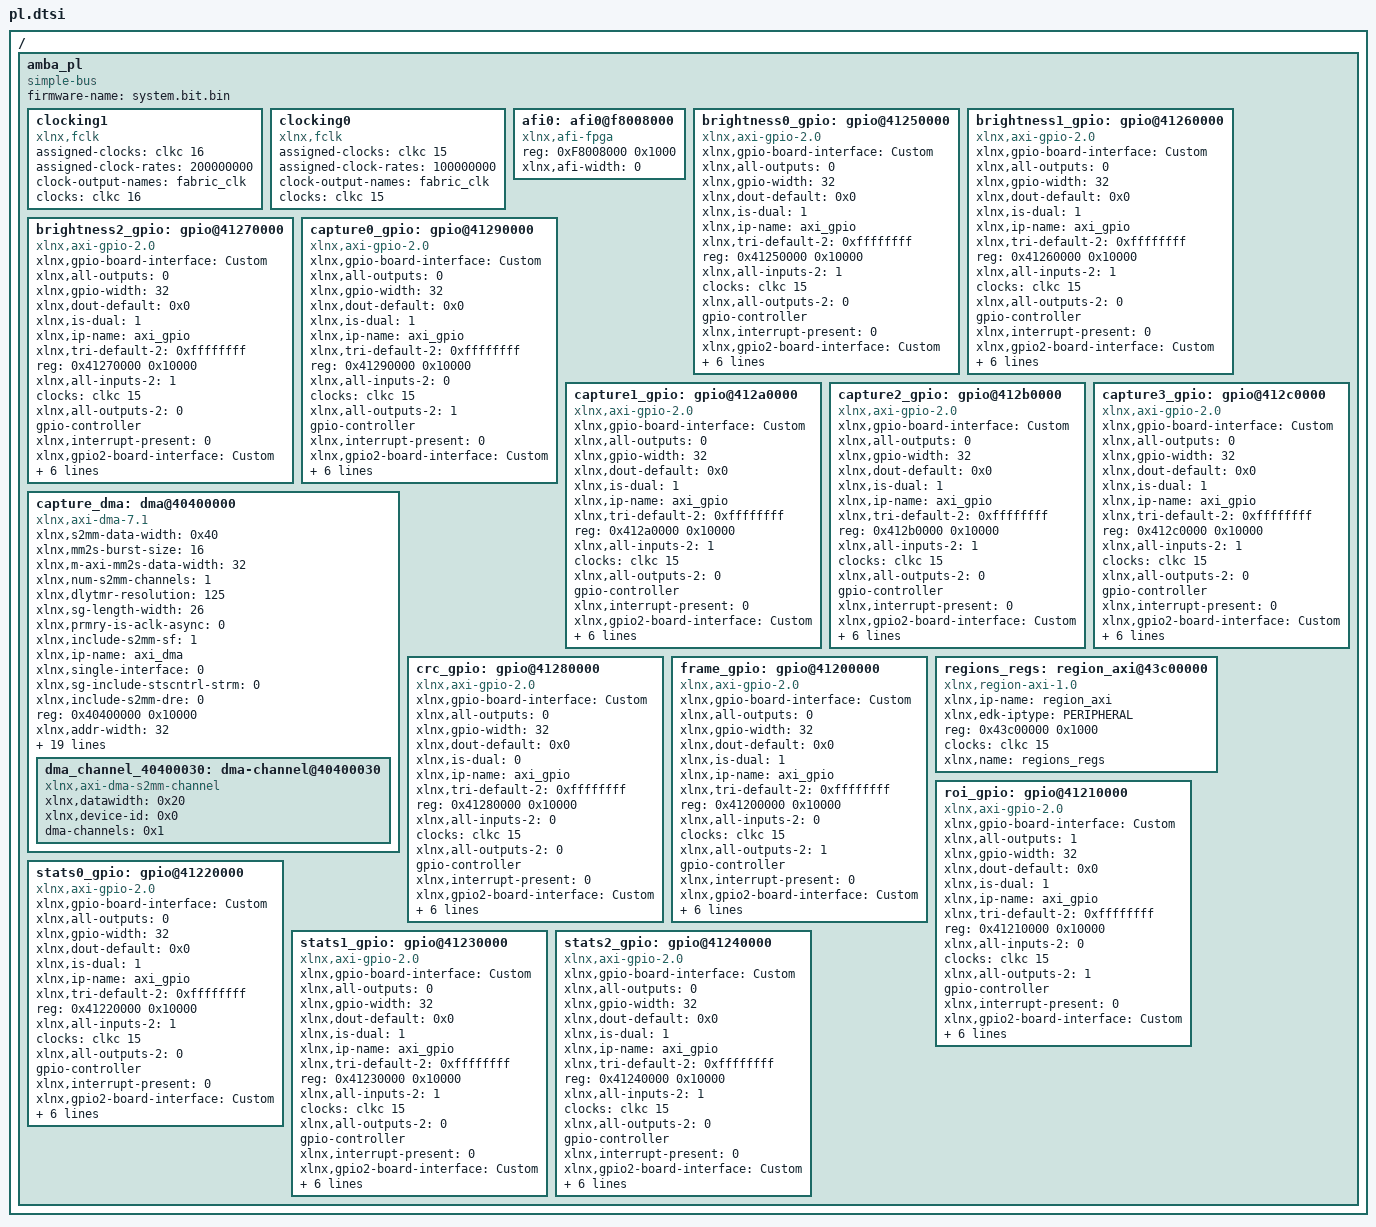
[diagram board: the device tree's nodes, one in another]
/ {
	amba_pl: amba_pl {
		ranges;
		compatible = "simple-bus";
		#address-cells = <1>;
		#size-cells = <1>;
		firmware-name = "system.bit.bin";
		clocking1: clocking1 {
			compatible = "xlnx,fclk";
			assigned-clocks = <&clkc 16>;
			assigned-clock-rates = <200000000>;
			#clock-cells = <0>;
			clock-output-names = "fabric_clk";
			clocks = <&clkc 16>;
		};
		clocking0: clocking0 {
			compatible = "xlnx,fclk";
			assigned-clocks = <&clkc 15>;
			assigned-clock-rates = <100000000>;
			#clock-cells = <0>;
			clock-output-names = "fabric_clk";
			clocks = <&clkc 15>;
		};
		afi0: afi0@f8008000 {
			status = "okay";
			compatible = "xlnx,afi-fpga";
			#address-cells = <1>;
			reg = <0xF8008000 0x1000>;
			#size-cells = <0>;
			xlnx,afi-width = <0>;
		};
		brightness0_gpio: gpio@41250000 {
			xlnx,gpio-board-interface = "Custom";
			compatible = "xlnx,axi-gpio-2.0" , "xlnx,xps-gpio-1.00.a";
			xlnx,all-outputs = <0>;
			#gpio-cells = <2>;
			xlnx,gpio-width = <32>;
			xlnx,dout-default = <0x0>;
			xlnx,is-dual = <1>;
			xlnx,ip-name = "axi_gpio";
			xlnx,tri-default-2 = <0xffffffff>;
			reg = <0x41250000 0x10000>;
			xlnx,all-inputs-2 = <1>;
			clocks = <&clkc 15>;
			xlnx,all-outputs-2 = <0>;
			gpio-controller;
			xlnx,interrupt-present = <0>;
			xlnx,gpio2-board-interface = "Custom";
			xlnx,edk-iptype = "PERIPHERAL";
			xlnx,dout-default-2 = <0x0>;
			status = "okay";
			xlnx,gpio2-width = <32>;
			clock-names = "s_axi_aclk";
			xlnx,tri-default = <0xffffffff>;
			xlnx,name = "brightness0_gpio";
			xlnx,all-inputs = <1>;
		};
		brightness1_gpio: gpio@41260000 {
			xlnx,gpio-board-interface = "Custom";
			compatible = "xlnx,axi-gpio-2.0" , "xlnx,xps-gpio-1.00.a";
			xlnx,all-outputs = <0>;
			#gpio-cells = <2>;
			xlnx,gpio-width = <32>;
			xlnx,dout-default = <0x0>;
			xlnx,is-dual = <1>;
			xlnx,ip-name = "axi_gpio";
			xlnx,tri-default-2 = <0xffffffff>;
			reg = <0x41260000 0x10000>;
			xlnx,all-inputs-2 = <1>;
			clocks = <&clkc 15>;
			xlnx,all-outputs-2 = <0>;
			gpio-controller;
			xlnx,interrupt-present = <0>;
			xlnx,gpio2-board-interface = "Custom";
			xlnx,edk-iptype = "PERIPHERAL";
			xlnx,dout-default-2 = <0x0>;
			status = "okay";
			xlnx,gpio2-width = <32>;
			clock-names = "s_axi_aclk";
			xlnx,tri-default = <0xffffffff>;
			xlnx,name = "brightness1_gpio";
			xlnx,all-inputs = <1>;
		};
		brightness2_gpio: gpio@41270000 {
			xlnx,gpio-board-interface = "Custom";
			compatible = "xlnx,axi-gpio-2.0" , "xlnx,xps-gpio-1.00.a";
			xlnx,all-outputs = <0>;
			#gpio-cells = <2>;
			xlnx,gpio-width = <32>;
			xlnx,dout-default = <0x0>;
			xlnx,is-dual = <1>;
			xlnx,ip-name = "axi_gpio";
			xlnx,tri-default-2 = <0xffffffff>;
			reg = <0x41270000 0x10000>;
			xlnx,all-inputs-2 = <1>;
			clocks = <&clkc 15>;
			xlnx,all-outputs-2 = <0>;
			gpio-controller;
			xlnx,interrupt-present = <0>;
			xlnx,gpio2-board-interface = "Custom";
			xlnx,edk-iptype = "PERIPHERAL";
			xlnx,dout-default-2 = <0x0>;
			status = "okay";
			xlnx,gpio2-width = <32>;
			clock-names = "s_axi_aclk";
			xlnx,tri-default = <0xffffffff>;
			xlnx,name = "brightness2_gpio";
			xlnx,all-inputs = <1>;
		};
		capture0_gpio: gpio@41290000 {
			xlnx,gpio-board-interface = "Custom";
			compatible = "xlnx,axi-gpio-2.0" , "xlnx,xps-gpio-1.00.a";
			xlnx,all-outputs = <0>;
			#gpio-cells = <2>;
			xlnx,gpio-width = <32>;
			xlnx,dout-default = <0x0>;
			xlnx,is-dual = <1>;
			xlnx,ip-name = "axi_gpio";
			xlnx,tri-default-2 = <0xffffffff>;
			reg = <0x41290000 0x10000>;
			xlnx,all-inputs-2 = <0>;
			clocks = <&clkc 15>;
			xlnx,all-outputs-2 = <1>;
			gpio-controller;
			xlnx,interrupt-present = <0>;
			xlnx,gpio2-board-interface = "Custom";
			xlnx,edk-iptype = "PERIPHERAL";
			xlnx,dout-default-2 = <0x0>;
			status = "okay";
			xlnx,gpio2-width = <32>;
			clock-names = "s_axi_aclk";
			xlnx,tri-default = <0xffffffff>;
			xlnx,name = "capture0_gpio";
			xlnx,all-inputs = <1>;
		};
		capture1_gpio: gpio@412a0000 {
			xlnx,gpio-board-interface = "Custom";
			compatible = "xlnx,axi-gpio-2.0" , "xlnx,xps-gpio-1.00.a";
			xlnx,all-outputs = <0>;
			#gpio-cells = <2>;
			xlnx,gpio-width = <32>;
			xlnx,dout-default = <0x0>;
			xlnx,is-dual = <1>;
			xlnx,ip-name = "axi_gpio";
			xlnx,tri-default-2 = <0xffffffff>;
			reg = <0x412a0000 0x10000>;
			xlnx,all-inputs-2 = <1>;
			clocks = <&clkc 15>;
			xlnx,all-outputs-2 = <0>;
			gpio-controller;
			xlnx,interrupt-present = <0>;
			xlnx,gpio2-board-interface = "Custom";
			xlnx,edk-iptype = "PERIPHERAL";
			xlnx,dout-default-2 = <0x0>;
			status = "okay";
			xlnx,gpio2-width = <32>;
			clock-names = "s_axi_aclk";
			xlnx,tri-default = <0xffffffff>;
			xlnx,name = "capture1_gpio";
			xlnx,all-inputs = <1>;
		};
		capture2_gpio: gpio@412b0000 {
			xlnx,gpio-board-interface = "Custom";
			compatible = "xlnx,axi-gpio-2.0" , "xlnx,xps-gpio-1.00.a";
			xlnx,all-outputs = <0>;
			#gpio-cells = <2>;
			xlnx,gpio-width = <32>;
			xlnx,dout-default = <0x0>;
			xlnx,is-dual = <1>;
			xlnx,ip-name = "axi_gpio";
			xlnx,tri-default-2 = <0xffffffff>;
			reg = <0x412b0000 0x10000>;
			xlnx,all-inputs-2 = <1>;
			clocks = <&clkc 15>;
			xlnx,all-outputs-2 = <0>;
			gpio-controller;
			xlnx,interrupt-present = <0>;
			xlnx,gpio2-board-interface = "Custom";
			xlnx,edk-iptype = "PERIPHERAL";
			xlnx,dout-default-2 = <0x0>;
			status = "okay";
			xlnx,gpio2-width = <32>;
			clock-names = "s_axi_aclk";
			xlnx,tri-default = <0xffffffff>;
			xlnx,name = "capture2_gpio";
			xlnx,all-inputs = <1>;
		};
		capture3_gpio: gpio@412c0000 {
			xlnx,gpio-board-interface = "Custom";
			compatible = "xlnx,axi-gpio-2.0" , "xlnx,xps-gpio-1.00.a";
			xlnx,all-outputs = <0>;
			#gpio-cells = <2>;
			xlnx,gpio-width = <32>;
			xlnx,dout-default = <0x0>;
			xlnx,is-dual = <1>;
			xlnx,ip-name = "axi_gpio";
			xlnx,tri-default-2 = <0xffffffff>;
			reg = <0x412c0000 0x10000>;
			xlnx,all-inputs-2 = <1>;
			clocks = <&clkc 15>;
			xlnx,all-outputs-2 = <0>;
			gpio-controller;
			xlnx,interrupt-present = <0>;
			xlnx,gpio2-board-interface = "Custom";
			xlnx,edk-iptype = "PERIPHERAL";
			xlnx,dout-default-2 = <0x0>;
			status = "okay";
			xlnx,gpio2-width = <32>;
			clock-names = "s_axi_aclk";
			xlnx,tri-default = <0xffffffff>;
			xlnx,name = "capture3_gpio";
			xlnx,all-inputs = <1>;
		};
		capture_dma: dma@40400000 {
			compatible = "xlnx,axi-dma-7.1" , "xlnx,axi-dma-1.00.a";
			xlnx,s2mm-data-width = <0x40>;
			xlnx,mm2s-burst-size = <16>;
			xlnx,m-axi-mm2s-data-width = <32>;
			xlnx,num-s2mm-channels = <1>;
			xlnx,dlytmr-resolution = <125>;
			xlnx,sg-length-width = <26>;
			xlnx,prmry-is-aclk-async = <0>;
			xlnx,include-s2mm-sf = <1>;
			#dma-cells = <1>;
			xlnx,ip-name = "axi_dma";
			xlnx,single-interface = <0>;
			xlnx,sg-include-stscntrl-strm = <0>;
			xlnx,include-s2mm-dre = <0>;
			reg = <0x40400000 0x10000>;
			xlnx,addr-width = <32>;
			xlnx,include-s2mm = <1>;
			clocks = <&clkc 15>, <&clkc 15>, <&clkc 15>;
			xlnx,s-axis-s2mm-tdata-width = <32>;
			xlnx,micro-dma = <0>;
			xlnx,increase-throughput = <0>;
			xlnx,mm2s-data-width = <0x20>;
			xlnx,addrwidth = <0x20>;
			xlnx,include-sg;
			xlnx,sg-use-stsapp-length = <0>;
			xlnx,m-axis-mm2s-tdata-width = <32>;
			xlnx,edk-iptype = "PERIPHERAL";
			xlnx,s2mm-burst-size = <64>;
			xlnx,m-axi-s2mm-data-width = <64>;
			xlnx,num-mm2s-channels = <1>;
			xlnx,enable-multi-channel = <0>;
			status = "okay";
			xlnx,include-mm2s-sf = <1>;
			clock-names = "m_axi_s2mm_aclk" , "m_axi_sg_aclk" , "s_axi_lite_aclk";
			xlnx,include-mm2s = <0>;
			xlnx,include-mm2s-dre = <0>;
			xlnx,name = "capture_dma";
			dma_channel_40400030: dma-channel@40400030 {
				xlnx,datawidth = <0x20>;
				xlnx,device-id = <0x0>;
				compatible = "xlnx,axi-dma-s2mm-channel";
				dma-channels = <0x1>;
			};
		};
		crc_gpio: gpio@41280000 {
			xlnx,gpio-board-interface = "Custom";
			compatible = "xlnx,axi-gpio-2.0" , "xlnx,xps-gpio-1.00.a";
			xlnx,all-outputs = <0>;
			#gpio-cells = <2>;
			xlnx,gpio-width = <32>;
			xlnx,dout-default = <0x0>;
			xlnx,is-dual = <0>;
			xlnx,ip-name = "axi_gpio";
			xlnx,tri-default-2 = <0xffffffff>;
			reg = <0x41280000 0x10000>;
			xlnx,all-inputs-2 = <0>;
			clocks = <&clkc 15>;
			xlnx,all-outputs-2 = <0>;
			gpio-controller;
			xlnx,interrupt-present = <0>;
			xlnx,gpio2-board-interface = "Custom";
			xlnx,edk-iptype = "PERIPHERAL";
			xlnx,dout-default-2 = <0x0>;
			status = "okay";
			xlnx,gpio2-width = <32>;
			clock-names = "s_axi_aclk";
			xlnx,tri-default = <0xffffffff>;
			xlnx,name = "crc_gpio";
			xlnx,all-inputs = <1>;
		};
		frame_gpio: gpio@41200000 {
			xlnx,gpio-board-interface = "Custom";
			compatible = "xlnx,axi-gpio-2.0" , "xlnx,xps-gpio-1.00.a";
			xlnx,all-outputs = <0>;
			#gpio-cells = <2>;
			xlnx,gpio-width = <32>;
			xlnx,dout-default = <0x0>;
			xlnx,is-dual = <1>;
			xlnx,ip-name = "axi_gpio";
			xlnx,tri-default-2 = <0xffffffff>;
			reg = <0x41200000 0x10000>;
			xlnx,all-inputs-2 = <0>;
			clocks = <&clkc 15>;
			xlnx,all-outputs-2 = <1>;
			gpio-controller;
			xlnx,interrupt-present = <0>;
			xlnx,gpio2-board-interface = "Custom";
			xlnx,edk-iptype = "PERIPHERAL";
			xlnx,dout-default-2 = <0x0>;
			status = "okay";
			xlnx,gpio2-width = <32>;
			clock-names = "s_axi_aclk";
			xlnx,tri-default = <0xffffffff>;
			xlnx,name = "frame_gpio";
			xlnx,all-inputs = <1>;
		};
		regions_regs: region_axi@43c00000 {
			compatible = "xlnx,region-axi-1.0";
			status = "okay";
			clock-names = "s_axi_aclk";
			xlnx,ip-name = "region_axi";
			xlnx,edk-iptype = "PERIPHERAL";
			reg = <0x43c00000 0x1000>;
			clocks = <&clkc 15>;
			xlnx,name = "regions_regs";
		};
		roi_gpio: gpio@41210000 {
			xlnx,gpio-board-interface = "Custom";
			compatible = "xlnx,axi-gpio-2.0" , "xlnx,xps-gpio-1.00.a";
			xlnx,all-outputs = <1>;
			#gpio-cells = <2>;
			xlnx,gpio-width = <32>;
			xlnx,dout-default = <0x0>;
			xlnx,is-dual = <1>;
			xlnx,ip-name = "axi_gpio";
			xlnx,tri-default-2 = <0xffffffff>;
			reg = <0x41210000 0x10000>;
			xlnx,all-inputs-2 = <0>;
			clocks = <&clkc 15>;
			xlnx,all-outputs-2 = <1>;
			gpio-controller;
			xlnx,interrupt-present = <0>;
			xlnx,gpio2-board-interface = "Custom";
			xlnx,edk-iptype = "PERIPHERAL";
			xlnx,dout-default-2 = <0x0>;
			status = "okay";
			xlnx,gpio2-width = <32>;
			clock-names = "s_axi_aclk";
			xlnx,tri-default = <0xffffffff>;
			xlnx,name = "roi_gpio";
			xlnx,all-inputs = <0>;
		};
		stats0_gpio: gpio@41220000 {
			xlnx,gpio-board-interface = "Custom";
			compatible = "xlnx,axi-gpio-2.0" , "xlnx,xps-gpio-1.00.a";
			xlnx,all-outputs = <0>;
			#gpio-cells = <2>;
			xlnx,gpio-width = <32>;
			xlnx,dout-default = <0x0>;
			xlnx,is-dual = <1>;
			xlnx,ip-name = "axi_gpio";
			xlnx,tri-default-2 = <0xffffffff>;
			reg = <0x41220000 0x10000>;
			xlnx,all-inputs-2 = <1>;
			clocks = <&clkc 15>;
			xlnx,all-outputs-2 = <0>;
			gpio-controller;
			xlnx,interrupt-present = <0>;
			xlnx,gpio2-board-interface = "Custom";
			xlnx,edk-iptype = "PERIPHERAL";
			xlnx,dout-default-2 = <0x0>;
			status = "okay";
			xlnx,gpio2-width = <32>;
			clock-names = "s_axi_aclk";
			xlnx,tri-default = <0xffffffff>;
			xlnx,name = "stats0_gpio";
			xlnx,all-inputs = <1>;
		};
		stats1_gpio: gpio@41230000 {
			xlnx,gpio-board-interface = "Custom";
			compatible = "xlnx,axi-gpio-2.0" , "xlnx,xps-gpio-1.00.a";
			xlnx,all-outputs = <0>;
			#gpio-cells = <2>;
			xlnx,gpio-width = <32>;
			xlnx,dout-default = <0x0>;
			xlnx,is-dual = <1>;
			xlnx,ip-name = "axi_gpio";
			xlnx,tri-default-2 = <0xffffffff>;
			reg = <0x41230000 0x10000>;
			xlnx,all-inputs-2 = <1>;
			clocks = <&clkc 15>;
			xlnx,all-outputs-2 = <0>;
			gpio-controller;
			xlnx,interrupt-present = <0>;
			xlnx,gpio2-board-interface = "Custom";
			xlnx,edk-iptype = "PERIPHERAL";
			xlnx,dout-default-2 = <0x0>;
			status = "okay";
			xlnx,gpio2-width = <32>;
			clock-names = "s_axi_aclk";
			xlnx,tri-default = <0xffffffff>;
			xlnx,name = "stats1_gpio";
			xlnx,all-inputs = <1>;
		};
		stats2_gpio: gpio@41240000 {
			xlnx,gpio-board-interface = "Custom";
			compatible = "xlnx,axi-gpio-2.0" , "xlnx,xps-gpio-1.00.a";
			xlnx,all-outputs = <0>;
			#gpio-cells = <2>;
			xlnx,gpio-width = <32>;
			xlnx,dout-default = <0x0>;
			xlnx,is-dual = <1>;
			xlnx,ip-name = "axi_gpio";
			xlnx,tri-default-2 = <0xffffffff>;
			reg = <0x41240000 0x10000>;
			xlnx,all-inputs-2 = <1>;
			clocks = <&clkc 15>;
			xlnx,all-outputs-2 = <0>;
			gpio-controller;
			xlnx,interrupt-present = <0>;
			xlnx,gpio2-board-interface = "Custom";
			xlnx,edk-iptype = "PERIPHERAL";
			xlnx,dout-default-2 = <0x0>;
			status = "okay";
			xlnx,gpio2-width = <32>;
			clock-names = "s_axi_aclk";
			xlnx,tri-default = <0xffffffff>;
			xlnx,name = "stats2_gpio";
			xlnx,all-inputs = <1>;
		};
	};
};
